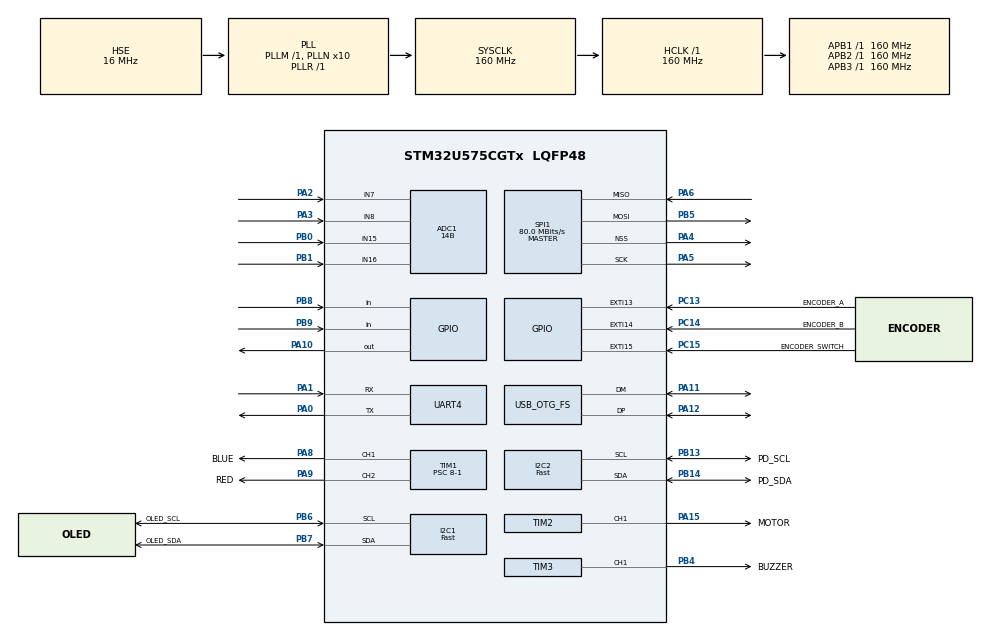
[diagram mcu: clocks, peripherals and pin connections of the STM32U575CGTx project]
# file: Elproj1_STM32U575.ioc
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ADC1.NbrOfConversion=1
ADC1.Resolution=ADC_RESOLUTION_14B
ADC1.master=1
CORTEX_M33_NS.userName=CORTEX_M33
I2C1.I2C_Speed_Mode=I2C_Fast
I2C1.Timing=0x00F07BFF
I2C2.I2C_Speed_Mode=I2C_Fast
I2C2.Timing=0x00F07BFF
Mcu.Family=STM32U5
Mcu.Name=STM32U575CGTx
Mcu.Package=LQFP48
NVIC.EXTI13_IRQn=true\:0\:0\:false\:false\:true\:true\:true\:true
NVIC.EXTI14_IRQn=true\:0\:0\:false\:false\:true\:true\:true\:true
NVIC.EXTI15_IRQn=true\:0\:0\:false\:false\:true\:true\:true\:true
NVIC.PriorityGroup=NVIC_PRIORITYGROUP_4
PA0.Mode=Asynchronous
PA0.Signal=UART4_TX
PA1.Mode=Asynchronous
PA1.Signal=UART4_RX
PA10.Signal=GPIO_Output
PA11.Mode=Host_Only
PA11.Signal=USB_OTG_FS_DM
PA12.Mode=Host_Only
PA12.Signal=USB_OTG_FS_DP
PA13\ (JTMS/SWDIO).Mode=Trace_Asynchronous_SW
PA13\ (JTMS/SWDIO).Signal=DEBUG_JTMS-SWDIO
PA14\ (JTCK/SWCLK).Mode=Trace_Asynchronous_SW
PA14\ (JTCK/SWCLK).Signal=DEBUG_JTCK-SWCLK
PA15\ (JTDI).GPIO_Label=MOTOR
PA15\ (JTDI).Signal=S_TIM2_CH1
PA2.Mode=IN7-Single-Ended
PA2.Signal=ADC1_IN7
PA3.Mode=IN8-Single-Ended
PA3.Signal=ADC1_IN8
PA4.Mode=NSS_Signal_Hard_Output
PA4.Signal=SPI1_NSS
PA5.Mode=Full_Duplex_Master
PA5.Signal=SPI1_SCK
PA6.Mode=Full_Duplex_Master
PA6.Signal=SPI1_MISO
PA8.GPIO_Label=BLUE
PA8.Signal=S_TIM1_CH1
PA9.GPIO_Label=RED
PA9.Signal=S_TIM1_CH2
PB0.Mode=IN15-Single-Ended
PB0.Signal=ADC1_IN15
PB1.Mode=IN16-Single-Ended
PB1.Signal=ADC1_IN16
PB13.GPIO_Label=PD_SCL
PB13.Mode=I2C
PB13.Signal=I2C2_SCL
PB14.GPIO_Label=PD_SDA
PB14.Mode=I2C
PB14.Signal=I2C2_SDA
PB3\ (JTDO/TRACESWO).Mode=Trace_Asynchronous_SW
PB3\ (JTDO/TRACESWO).Signal=DEBUG_JTDO-SWO
PB4\ (NJTRST).GPIO_Label=BUZZER
PB4\ (NJTRST).Signal=S_TIM3_CH1
PB5.Mode=Full_Duplex_Master
PB5.Signal=SPI1_MOSI
PB6.GPIO_Label=OLED_SCL
PB6.Mode=I2C
PB6.Signal=I2C1_SCL
PB7.GPIO_Label=OLED_SDA
PB7.Mode=I2C
PB7.Signal=I2C1_SDA
PB8.Signal=GPIO_Input
PB9.Signal=GPIO_Input
PC13.GPIO_Label=ENCODER_A
PC13.Signal=GPXTI13
PC14-OSC32_IN\ (PC14).GPIO_Label=ENCODER_B
PC14-OSC32_IN\ (PC14).Signal=GPXTI14
PC15-OSC32_OUT\ (PC15).GPIO_Label=ENCODER_SWITCH
PC15-OSC32_OUT\ (PC15).GPIO_ModeDefaultEXTI=GPIO_MODE_IT_RISING
PC15-OSC32_OUT\ (PC15).Signal=GPXTI15
PH0-OSC_IN\ (PH0).Mode=HSE-External-Oscillator
PH0-OSC_IN\ (PH0).Signal=RCC_OSC_IN
PH1-OSC_OUT\ (PH1).Mode=HSE-External-Oscillator
PH1-OSC_OUT\ (PH1).Signal=RCC_OSC_OUT
ProjectManager.HeapSize=0x200
ProjectManager.StackSize=0x400
ProjectManager.TargetToolchain=STM32CubeIDE
RCC.ADCFreq_Value=16000000
RCC.AHBFreq_Value=160000000
RCC.APB1Freq_Value=160000000
RCC.APB1TimFreq_Value=160000000
RCC.APB2Freq_Value=160000000
RCC.APB2TimFreq_Value=160000000
RCC.APB3Freq_Value=160000000
RCC.CortexFreq_Value=160000000
RCC.EPOD_VALUE=16000000
RCC.HCLKFreq_Value=160000000
RCC.HSE_VALUE=16000000
RCC.HSI48_VALUE=48000000
RCC.HSI_VALUE=16000000
RCC.LSE_VALUE=32768
RCC.LSIDIV_VALUE=32000
RCC.MSI_VALUE=4000000
RCC.PLL1R=1
RCC.PLL2FRACN=0
RCC.PLL3FRACN=0
RCC.PLLFRACN=0
RCC.PLLN=10
RCC.PLLSourceVirtual=RCC_PLLSOURCE_HSE
RCC.SYSCLKFreq_VALUE=160000000
RCC.SYSCLKSource=RCC_SYSCLKSOURCE_PLLCLK
RCC.USBFreq_Value=48000000
RCC.VCOOutputFreq_Value=160000000
SH.S_TIM1_CH1.0=TIM1_CH1,PWM Generation1 CH1
SH.S_TIM1_CH2.0=TIM1_CH2,PWM Generation2 CH2
SH.S_TIM2_CH1.0=TIM2_CH1,PWM Generation1 CH1
SH.S_TIM3_CH1.0=TIM3_CH1,PWM Generation1 CH1
SPI1.BaudRatePrescaler=SPI_BAUDRATEPRESCALER_2
SPI1.CalculateBaudRate=80.0 MBits/s
SPI1.Direction=SPI_DIRECTION_2LINES
SPI1.Mode=SPI_MODE_MASTER
SPI1.VirtualNSS=VM_NSSHARD
SPI1.VirtualType=VM_MASTER
TIM1.Channel-PWM\ Generation1\ CH1=TIM_CHANNEL_1
TIM1.Channel-PWM\ Generation2\ CH2=TIM_CHANNEL_2
TIM1.PeriodNoDither=100-1
TIM1.Prescaler=8-1
TIM2.Channel-PWM\ Generation1\ CH1=TIM_CHANNEL_1
TIM2.PeriodNoDither=20000-1
TIM2.Prescaler=8-1
TIM3.Channel-PWM\ Generation1\ CH1=TIM_CHANNEL_1
TIM3.PeriodNoDither=50
TIM3.Prescaler=8-1
USB_OTG_FS.VirtualMode=Host_Only
USB_OTG_FS.phy_itface=HCD_PHY_EMBEDDED
VP_LPBAMQUEUE_VS_QUEUE.Mode=QUEUEMODE
VP_LPBAM_VS_SIG1.Mode=SmartRun
VP_LPBAM_VS_SIG4.Mode=LPDMA1
VP_MEMORYMAP_VS_MEMORYMAP.Mode=CurAppReg
VP_PWR_VS_SECSignals.Mode=Security/Privilege
VP_PWR_Vdda.Mode=isolationVdda
VP_TIM1_VS_ClockSourceINT.Mode=Internal
VP_TIM2_VS_ClockSourceINT.Mode=Internal
board=custom

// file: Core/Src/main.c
/* USER CODE BEGIN Header */
/**
  ******************************************************************************
  * @file           : main.c
  * @brief          : Main program body
  ******************************************************************************
  * @attention
  *
  * Copyright (c) 2025 STMicroelectronics.
  * All rights reserved.
  *
  * This software is licensed under terms that can be found in the LICENSE file
  * in the root directory of this software component.
  * If no LICENSE file comes with this software, it is provided AS-IS.
  *
  ******************************************************************************
  */
/* USER CODE END Header */
#include "main.h"

ADC_HandleTypeDef hadc1;

I2C_HandleTypeDef hi2c1;
I2C_HandleTypeDef hi2c2;

SPI_HandleTypeDef hspi1;

TIM_HandleTypeDef htim1;
TIM_HandleTypeDef htim2;
TIM_HandleTypeDef htim3;

UART_HandleTypeDef huart4;

HCD_HandleTypeDef hhcd_USB_OTG_FS;

void SystemClock_Config(void);
static void MX_GPIO_Init(void);
static void MX_ADC1_Init(void);
static void MX_I2C1_Init(void);
static void MX_SPI1_Init(void);
static void MX_TIM2_Init(void);
static void MX_UART4_Init(void);
static void MX_USB_OTG_FS_HCD_Init(void);
static void MX_I2C2_Init(void);
static void MX_TIM1_Init(void);
static void MX_TIM3_Init(void);

int main(void)
{

  /* MCU Configuration--------------------------------------------------------*/

  /* Reset of all peripherals, Initializes the Flash interface and the Systick. */
  HAL_Init();

  /* Configure the system clock */
  SystemClock_Config();

  /* Initialize all configured peripherals */
  MX_GPIO_Init();
  MX_ADC1_Init();
  MX_I2C1_Init();
  MX_SPI1_Init();
  MX_TIM2_Init();
  MX_UART4_Init();
  MX_USB_OTG_FS_HCD_Init();
  MX_I2C2_Init();
  MX_TIM1_Init();
  MX_TIM3_Init();

  /* Infinite loop */
  while (1)
  {

    /* USER CODE BEGIN 3 */
	  HAL_GPIO_TogglePin(GPIOA, GPIO_PIN_10);
	  printf("SKIBIDI SKIBIDI HAWK TUAH HAWK\n");
	  ITM_SendChar('a');
	  HAL_Delay(1000);
  }
  /* USER CODE END 3 */
}

void SystemClock_Config(void)
{
  RCC_OscInitTypeDef RCC_OscInitStruct = {0};
  RCC_ClkInitTypeDef RCC_ClkInitStruct = {0};

  /** Configure the main internal regulator output voltage
  */
  if (HAL_PWREx_ControlVoltageScaling(PWR_REGULATOR_VOLTAGE_SCALE1) != HAL_OK)
  {
    Error_Handler();
  }

  /** Initializes the CPU, AHB and APB buses clocks
  */
  RCC_OscInitStruct.OscillatorType = RCC_OSCILLATORTYPE_HSI48|RCC_OSCILLATORTYPE_HSI
                              |RCC_OSCILLATORTYPE_HSE;
  RCC_OscInitStruct.HSEState = RCC_HSE_ON;
  RCC_OscInitStruct.HSIState = RCC_HSI_ON;
  RCC_OscInitStruct.HSI48State = RCC_HSI48_ON;
  RCC_OscInitStruct.HSICalibrationValue = RCC_HSICALIBRATION_DEFAULT;
  RCC_OscInitStruct.PLL.PLLState = RCC_PLL_ON;
  RCC_OscInitStruct.PLL.PLLSource = RCC_PLLSOURCE_HSE;
  RCC_OscInitStruct.PLL.PLLMBOOST = RCC_PLLMBOOST_DIV1;
  RCC_OscInitStruct.PLL.PLLM = 1;
  RCC_OscInitStruct.PLL.PLLN = 10;
  RCC_OscInitStruct.PLL.PLLP = 2;
  RCC_OscInitStruct.PLL.PLLQ = 2;
  RCC_OscInitStruct.PLL.PLLR = 1;
  RCC_OscInitStruct.PLL.PLLRGE = RCC_PLLVCIRANGE_1;
  RCC_OscInitStruct.PLL.PLLFRACN = 0;
  if (HAL_RCC_OscConfig(&RCC_OscInitStruct) != HAL_OK)
  {
    Error_Handler();
  }

  /** Initializes the CPU, AHB and APB buses clocks
  */
  RCC_ClkInitStruct.ClockType = RCC_CLOCKTYPE_HCLK|RCC_CLOCKTYPE_SYSCLK
                              |RCC_CLOCKTYPE_PCLK1|RCC_CLOCKTYPE_PCLK2
                              |RCC_CLOCKTYPE_PCLK3;
  RCC_ClkInitStruct.SYSCLKSource = RCC_SYSCLKSOURCE_PLLCLK;
  RCC_ClkInitStruct.AHBCLKDivider = RCC_SYSCLK_DIV1;
  RCC_ClkInitStruct.APB1CLKDivider = RCC_HCLK_DIV1;
  RCC_ClkInitStruct.APB2CLKDivider = RCC_HCLK_DIV1;
  RCC_ClkInitStruct.APB3CLKDivider = RCC_HCLK_DIV1;

  if (HAL_RCC_ClockConfig(&RCC_ClkInitStruct, FLASH_LATENCY_4) != HAL_OK)
  {
    Error_Handler();
  }
}

static void MX_ADC1_Init(void)
{

  /** Common config
  */
  hadc1.Instance = ADC1;
  hadc1.Init.ClockPrescaler = ADC_CLOCK_ASYNC_DIV1;
  hadc1.Init.Resolution = ADC_RESOLUTION_14B;
  hadc1.Init.GainCompensation = 0;
  hadc1.Init.ScanConvMode = ADC_SCAN_DISABLE;
  hadc1.Init.EOCSelection = ADC_EOC_SINGLE_CONV;
  hadc1.Init.LowPowerAutoWait = DISABLE;
  hadc1.Init.ContinuousConvMode = DISABLE;
  hadc1.Init.NbrOfConversion = 1;
  hadc1.Init.DiscontinuousConvMode = DISABLE;
  hadc1.Init.DMAContinuousRequests = DISABLE;
  hadc1.Init.TriggerFrequencyMode = ADC_TRIGGER_FREQ_HIGH;
  hadc1.Init.Overrun = ADC_OVR_DATA_PRESERVED;
  hadc1.Init.LeftBitShift = ADC_LEFTBITSHIFT_NONE;
  hadc1.Init.ConversionDataManagement = ADC_CONVERSIONDATA_DR;
  hadc1.Init.OversamplingMode = DISABLE;
  if (HAL_ADC_Init(&hadc1) != HAL_OK)
  {
    Error_Handler();
  }

}

static void MX_I2C1_Init(void)
{

  hi2c1.Instance = I2C1;
  hi2c1.Init.Timing = 0x00F07BFF;
  hi2c1.Init.OwnAddress1 = 0;
  hi2c1.Init.AddressingMode = I2C_ADDRESSINGMODE_7BIT;
  hi2c1.Init.DualAddressMode = I2C_DUALADDRESS_DISABLE;
  hi2c1.Init.OwnAddress2 = 0;
  hi2c1.Init.OwnAddress2Masks = I2C_OA2_NOMASK;
  hi2c1.Init.GeneralCallMode = I2C_GENERALCALL_DISABLE;
  hi2c1.Init.NoStretchMode = I2C_NOSTRETCH_DISABLE;
  if (HAL_I2C_Init(&hi2c1) != HAL_OK)
  {
    Error_Handler();
  }

  /** Configure Analogue filter
  */
  if (HAL_I2CEx_ConfigAnalogFilter(&hi2c1, I2C_ANALOGFILTER_ENABLE) != HAL_OK)
  {
    Error_Handler();
  }

  /** Configure Digital filter
  */
  if (HAL_I2CEx_ConfigDigitalFilter(&hi2c1, 0) != HAL_OK)
  {
    Error_Handler();
  }

}

static void MX_I2C2_Init(void)
{

  hi2c2.Instance = I2C2;
  hi2c2.Init.Timing = 0x00F07BFF;
  hi2c2.Init.OwnAddress1 = 0;
  hi2c2.Init.AddressingMode = I2C_ADDRESSINGMODE_7BIT;
  hi2c2.Init.DualAddressMode = I2C_DUALADDRESS_DISABLE;
  hi2c2.Init.OwnAddress2 = 0;
  hi2c2.Init.OwnAddress2Masks = I2C_OA2_NOMASK;
  hi2c2.Init.GeneralCallMode = I2C_GENERALCALL_DISABLE;
  hi2c2.Init.NoStretchMode = I2C_NOSTRETCH_DISABLE;
  if (HAL_I2C_Init(&hi2c2) != HAL_OK)
  {
    Error_Handler();
  }

  /** Configure Analogue filter
  */
  if (HAL_I2CEx_ConfigAnalogFilter(&hi2c2, I2C_ANALOGFILTER_ENABLE) != HAL_OK)
  {
    Error_Handler();
  }

  /** Configure Digital filter
  */
  if (HAL_I2CEx_ConfigDigitalFilter(&hi2c2, 0) != HAL_OK)
  {
    Error_Handler();
  }

}

static void MX_SPI1_Init(void)
{

  SPI_AutonomousModeConfTypeDef HAL_SPI_AutonomousMode_Cfg_Struct = {0};

  /* SPI1 parameter configuration*/
  hspi1.Instance = SPI1;
  hspi1.Init.Mode = SPI_MODE_MASTER;
  hspi1.Init.Direction = SPI_DIRECTION_2LINES;
  hspi1.Init.DataSize = SPI_DATASIZE_4BIT;
  hspi1.Init.CLKPolarity = SPI_POLARITY_LOW;
  hspi1.Init.CLKPhase = SPI_PHASE_1EDGE;
  hspi1.Init.NSS = SPI_NSS_HARD_OUTPUT;
  hspi1.Init.BaudRatePrescaler = SPI_BAUDRATEPRESCALER_2;
  hspi1.Init.FirstBit = SPI_FIRSTBIT_MSB;
  hspi1.Init.TIMode = SPI_TIMODE_DISABLE;
  hspi1.Init.CRCCalculation = SPI_CRCCALCULATION_DISABLE;
  hspi1.Init.CRCPolynomial = 0x7;
  hspi1.Init.NSSPMode = SPI_NSS_PULSE_ENABLE;
  hspi1.Init.NSSPolarity = SPI_NSS_POLARITY_LOW;
  hspi1.Init.FifoThreshold = SPI_FIFO_THRESHOLD_01DATA;
  hspi1.Init.MasterSSIdleness = SPI_MASTER_SS_IDLENESS_00CYCLE;
  hspi1.Init.MasterInterDataIdleness = SPI_MASTER_INTERDATA_IDLENESS_00CYCLE;
  hspi1.Init.MasterReceiverAutoSusp = SPI_MASTER_RX_AUTOSUSP_DISABLE;
  hspi1.Init.MasterKeepIOState = SPI_MASTER_KEEP_IO_STATE_DISABLE;
  hspi1.Init.IOSwap = SPI_IO_SWAP_DISABLE;
  hspi1.Init.ReadyMasterManagement = SPI_RDY_MASTER_MANAGEMENT_INTERNALLY;
  hspi1.Init.ReadyPolarity = SPI_RDY_POLARITY_HIGH;
  if (HAL_SPI_Init(&hspi1) != HAL_OK)
  {
    Error_Handler();
  }
  HAL_SPI_AutonomousMode_Cfg_Struct.TriggerState = SPI_AUTO_MODE_DISABLE;
  HAL_SPI_AutonomousMode_Cfg_Struct.TriggerSelection = SPI_GRP1_GPDMA_CH0_TCF_TRG;
  HAL_SPI_AutonomousMode_Cfg_Struct.TriggerPolarity = SPI_TRIG_POLARITY_RISING;
  if (HAL_SPIEx_SetConfigAutonomousMode(&hspi1, &HAL_SPI_AutonomousMode_Cfg_Struct) != HAL_OK)
  {
    Error_Handler();
  }

}

static void MX_TIM1_Init(void)
{

  TIM_ClockConfigTypeDef sClockSourceConfig = {0};
  TIM_MasterConfigTypeDef sMasterConfig = {0};
  TIM_OC_InitTypeDef sConfigOC = {0};
  TIM_BreakDeadTimeConfigTypeDef sBreakDeadTimeConfig = {0};

  htim1.Instance = TIM1;
  htim1.Init.Prescaler = 8-1;
  htim1.Init.CounterMode = TIM_COUNTERMODE_UP;
  htim1.Init.Period = 99;
  htim1.Init.ClockDivision = TIM_CLOCKDIVISION_DIV1;
  htim1.Init.RepetitionCounter = 0;
  htim1.Init.AutoReloadPreload = TIM_AUTORELOAD_PRELOAD_DISABLE;
  if (HAL_TIM_Base_Init(&htim1) != HAL_OK)
  {
    Error_Handler();
  }
  sClockSourceConfig.ClockSource = TIM_CLOCKSOURCE_INTERNAL;
  if (HAL_TIM_ConfigClockSource(&htim1, &sClockSourceConfig) != HAL_OK)
  {
    Error_Handler();
  }
  if (HAL_TIM_PWM_Init(&htim1) != HAL_OK)
  {
    Error_Handler();
  }
  sMasterConfig.MasterOutputTrigger = TIM_TRGO_RESET;
  sMasterConfig.MasterOutputTrigger2 = TIM_TRGO2_RESET;
  sMasterConfig.MasterSlaveMode = TIM_MASTERSLAVEMODE_DISABLE;
  if (HAL_TIMEx_MasterConfigSynchronization(&htim1, &sMasterConfig) != HAL_OK)
  {
    Error_Handler();
  }
  sConfigOC.OCMode = TIM_OCMODE_PWM1;
  sConfigOC.Pulse = 0;
  sConfigOC.OCPolarity = TIM_OCPOLARITY_HIGH;
  sConfigOC.OCNPolarity = TIM_OCNPOLARITY_HIGH;
  sConfigOC.OCFastMode = TIM_OCFAST_DISABLE;
  sConfigOC.OCIdleState = TIM_OCIDLESTATE_RESET;
  sConfigOC.OCNIdleState = TIM_OCNIDLESTATE_RESET;
  if (HAL_TIM_PWM_ConfigChannel(&htim1, &sConfigOC, TIM_CHANNEL_1) != HAL_OK)
  {
    Error_Handler();
  }
  if (HAL_TIM_PWM_ConfigChannel(&htim1, &sConfigOC, TIM_CHANNEL_2) != HAL_OK)
  {
    Error_Handler();
  }
  sBreakDeadTimeConfig.OffStateRunMode = TIM_OSSR_DISABLE;
  sBreakDeadTimeConfig.OffStateIDLEMode = TIM_OSSI_DISABLE;
  sBreakDeadTimeConfig.LockLevel = TIM_LOCKLEVEL_OFF;
  sBreakDeadTimeConfig.DeadTime = 0;
  sBreakDeadTimeConfig.BreakState = TIM_BREAK_DISABLE;
  sBreakDeadTimeConfig.BreakPolarity = TIM_BREAKPOLARITY_HIGH;
  sBreakDeadTimeConfig.BreakFilter = 0;
  sBreakDeadTimeConfig.BreakAFMode = TIM_BREAK_AFMODE_INPUT;
  sBreakDeadTimeConfig.Break2State = TIM_BREAK2_DISABLE;
  sBreakDeadTimeConfig.Break2Polarity = TIM_BREAK2POLARITY_HIGH;
  sBreakDeadTimeConfig.Break2Filter = 0;
  sBreakDeadTimeConfig.Break2AFMode = TIM_BREAK_AFMODE_INPUT;
  sBreakDeadTimeConfig.AutomaticOutput = TIM_AUTOMATICOUTPUT_DISABLE;
  if (HAL_TIMEx_ConfigBreakDeadTime(&htim1, &sBreakDeadTimeConfig) != HAL_OK)
  {
    Error_Handler();
  }
  HAL_TIM_MspPostInit(&htim1);

}

static void MX_TIM2_Init(void)
{

  TIM_ClockConfigTypeDef sClockSourceConfig = {0};
  TIM_MasterConfigTypeDef sMasterConfig = {0};
  TIM_OC_InitTypeDef sConfigOC = {0};

  htim2.Instance = TIM2;
  htim2.Init.Prescaler = 8-1;
  htim2.Init.CounterMode = TIM_COUNTERMODE_UP;
  htim2.Init.Period = 19999;
  htim2.Init.ClockDivision = TIM_CLOCKDIVISION_DIV1;
  htim2.Init.AutoReloadPreload = TIM_AUTORELOAD_PRELOAD_DISABLE;
  if (HAL_TIM_Base_Init(&htim2) != HAL_OK)
  {
    Error_Handler();
  }
  sClockSourceConfig.ClockSource = TIM_CLOCKSOURCE_INTERNAL;
  if (HAL_TIM_ConfigClockSource(&htim2, &sClockSourceConfig) != HAL_OK)
  {
    Error_Handler();
  }
  if (HAL_TIM_PWM_Init(&htim2) != HAL_OK)
  {
    Error_Handler();
  }
  sMasterConfig.MasterOutputTrigger = TIM_TRGO_RESET;
  sMasterConfig.MasterSlaveMode = TIM_MASTERSLAVEMODE_DISABLE;
  if (HAL_TIMEx_MasterConfigSynchronization(&htim2, &sMasterConfig) != HAL_OK)
  {
    Error_Handler();
  }
  sConfigOC.OCMode = TIM_OCMODE_PWM1;
  sConfigOC.Pulse = 0;
  sConfigOC.OCPolarity = TIM_OCPOLARITY_HIGH;
  sConfigOC.OCFastMode = TIM_OCFAST_DISABLE;
  if (HAL_TIM_PWM_ConfigChannel(&htim2, &sConfigOC, TIM_CHANNEL_1) != HAL_OK)
  {
    Error_Handler();
  }
  HAL_TIM_MspPostInit(&htim2);

}

static void MX_TIM3_Init(void)
{

  TIM_MasterConfigTypeDef sMasterConfig = {0};
  TIM_OC_InitTypeDef sConfigOC = {0};

  htim3.Instance = TIM3;
  htim3.Init.Prescaler = 8-1;
  htim3.Init.CounterMode = TIM_COUNTERMODE_UP;
  htim3.Init.Period = 50;
  htim3.Init.ClockDivision = TIM_CLOCKDIVISION_DIV1;
  htim3.Init.AutoReloadPreload = TIM_AUTORELOAD_PRELOAD_DISABLE;
  if (HAL_TIM_PWM_Init(&htim3) != HAL_OK)
  {
    Error_Handler();
  }
  sMasterConfig.MasterOutputTrigger = TIM_TRGO_RESET;
  sMasterConfig.MasterSlaveMode = TIM_MASTERSLAVEMODE_DISABLE;
  if (HAL_TIMEx_MasterConfigSynchronization(&htim3, &sMasterConfig) != HAL_OK)
  {
    Error_Handler();
  }
  sConfigOC.OCMode = TIM_OCMODE_PWM1;
  sConfigOC.Pulse = 0;
  sConfigOC.OCPolarity = TIM_OCPOLARITY_HIGH;
  sConfigOC.OCFastMode = TIM_OCFAST_DISABLE;
  if (HAL_TIM_PWM_ConfigChannel(&htim3, &sConfigOC, TIM_CHANNEL_1) != HAL_OK)
  {
    Error_Handler();
  }
  HAL_TIM_MspPostInit(&htim3);

}

static void MX_UART4_Init(void)
{

  huart4.Instance = UART4;
  huart4.Init.BaudRate = 115200;
  huart4.Init.WordLength = UART_WORDLENGTH_8B;
  huart4.Init.StopBits = UART_STOPBITS_1;
  huart4.Init.Parity = UART_PARITY_NONE;
  huart4.Init.Mode = UART_MODE_TX_RX;
  huart4.Init.HwFlowCtl = UART_HWCONTROL_NONE;
  huart4.Init.OverSampling = UART_OVERSAMPLING_16;
  huart4.Init.OneBitSampling = UART_ONE_BIT_SAMPLE_DISABLE;
  huart4.Init.ClockPrescaler = UART_PRESCALER_DIV1;
  huart4.AdvancedInit.AdvFeatureInit = UART_ADVFEATURE_NO_INIT;
  if (HAL_UART_Init(&huart4) != HAL_OK)
  {
    Error_Handler();
  }
  if (HAL_UARTEx_SetTxFifoThreshold(&huart4, UART_TXFIFO_THRESHOLD_1_8) != HAL_OK)
  {
    Error_Handler();
  }
  if (HAL_UARTEx_SetRxFifoThreshold(&huart4, UART_RXFIFO_THRESHOLD_1_8) != HAL_OK)
  {
    Error_Handler();
  }
  if (HAL_UARTEx_DisableFifoMode(&huart4) != HAL_OK)
  {
    Error_Handler();
  }

}

static void MX_USB_OTG_FS_HCD_Init(void)
{

  hhcd_USB_OTG_FS.Instance = USB_OTG_FS;
  hhcd_USB_OTG_FS.Init.Host_channels = 12;
  hhcd_USB_OTG_FS.Init.speed = HCD_SPEED_FULL;
  hhcd_USB_OTG_FS.Init.dma_enable = DISABLE;
  hhcd_USB_OTG_FS.Init.phy_itface = HCD_PHY_EMBEDDED;
  hhcd_USB_OTG_FS.Init.Sof_enable = DISABLE;
  hhcd_USB_OTG_FS.Init.vbus_sensing_enable = DISABLE;
  if (HAL_HCD_Init(&hhcd_USB_OTG_FS) != HAL_OK)
  {
    Error_Handler();
  }

}

static void MX_GPIO_Init(void)
{
  GPIO_InitTypeDef GPIO_InitStruct = {0};

  /* GPIO Ports Clock Enable */
  __HAL_RCC_GPIOC_CLK_ENABLE();
  __HAL_RCC_GPIOH_CLK_ENABLE();
  __HAL_RCC_GPIOA_CLK_ENABLE();
  __HAL_RCC_GPIOB_CLK_ENABLE();

  /*Configure GPIO pin Output Level */
  HAL_GPIO_WritePin(GPIOA, GPIO_PIN_10, GPIO_PIN_RESET);

  /*Configure GPIO pins : ENCODER_A_Pin ENCODER_B_Pin ENCODER_SWITCH_Pin */
  GPIO_InitStruct.Pin = ENCODER_A_Pin|ENCODER_B_Pin|ENCODER_SWITCH_Pin;
  GPIO_InitStruct.Mode = GPIO_MODE_IT_RISING;
  GPIO_InitStruct.Pull = GPIO_NOPULL;
  HAL_GPIO_Init(GPIOC, &GPIO_InitStruct);

  /*Configure GPIO pin : PA10 */
  GPIO_InitStruct.Pin = GPIO_PIN_10;
  GPIO_InitStruct.Mode = GPIO_MODE_OUTPUT_PP;
  GPIO_InitStruct.Pull = GPIO_NOPULL;
  GPIO_InitStruct.Speed = GPIO_SPEED_FREQ_LOW;
  HAL_GPIO_Init(GPIOA, &GPIO_InitStruct);

  /*Configure GPIO pins : PB8 PB9 */
  GPIO_InitStruct.Pin = GPIO_PIN_8|GPIO_PIN_9;
  GPIO_InitStruct.Mode = GPIO_MODE_INPUT;
  GPIO_InitStruct.Pull = GPIO_NOPULL;
  HAL_GPIO_Init(GPIOB, &GPIO_InitStruct);

  /* EXTI interrupt init*/
  HAL_NVIC_SetPriority(EXTI13_IRQn, 0, 0);
  HAL_NVIC_EnableIRQ(EXTI13_IRQn);

  HAL_NVIC_SetPriority(EXTI14_IRQn, 0, 0);
  HAL_NVIC_EnableIRQ(EXTI14_IRQn);

  HAL_NVIC_SetPriority(EXTI15_IRQn, 0, 0);
  HAL_NVIC_EnableIRQ(EXTI15_IRQn);

}

void Error_Handler(void)
{
  __disable_irq();
  while (1)
  {
  }
}
